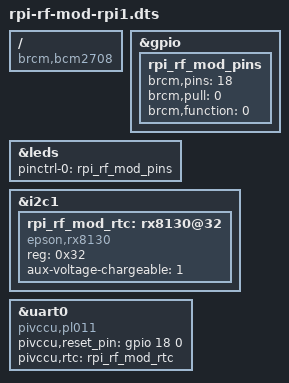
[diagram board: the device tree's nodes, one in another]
/dts-v1/;
/plugin/;

/*
** Device Tree Overlay for eQ-3 RPI-RF-MOD and
** HM-MOD-RPI-PCB for RaspberryPi1
**
** Copyright (c) 2018-2021 Jens Maus <mail@jens-maus.de>
** Licensed under Apache 2.0
**
*/

/ {
    compatible = "brcm,bcm2708";

    // fragment to ensure we have the correct gpio pin
    // setup for the RPI-RF-MOD
    fragment@0 {
        target = <&gpio>;
        __overlay__ {
            rpi_rf_mod_pins: rpi_rf_mod_pins {
                brcm,pins = <18>;    // 18=reset (HM-MOD-RPI-PCB)
                brcm,pull = <0>;     // 18=no-pullup
                brcm,function = <0>; // 18=input
            };
        };
    };

    // fragment to define dedicated led nodes for
    // each separate led supported by the RPI-RF-MOD
    fragment@1 {
        target = <&leds>;
        __overlay__ {
            pinctrl-names = "default";
            pinctrl-0 = <&rpi_rf_mod_pins>;
        };
    };

    // fragment to define settings for the rx8130 RTC clock
    // of the RPI-RF-MOD
    fragment@2 {
        target = <&i2c1>;
        __overlay__ {
            #address-cells = <1>;
            #size-cells = <0>;
            status = "okay";

            rpi_rf_mod_rtc: rx8130@32 {
                compatible = "epson,rx8130";
                reg = <0x32>;
                status = "okay";
                aux-voltage-chargeable = <1>;
            };
        };
    };

    // fragment to define uart/serial dependencies for
    // generic_raw_uart
    fragment@3 {
        target = <&uart0>;
        __overlay__ {
            compatible = "pivccu,pl011";
            pivccu,reset_pin = <&gpio 18 0>; // HM-MOD-RPI-PCB
            pivccu,rtc = <&rpi_rf_mod_rtc>;  // RPI-RF-MOD
        };
    };
};
